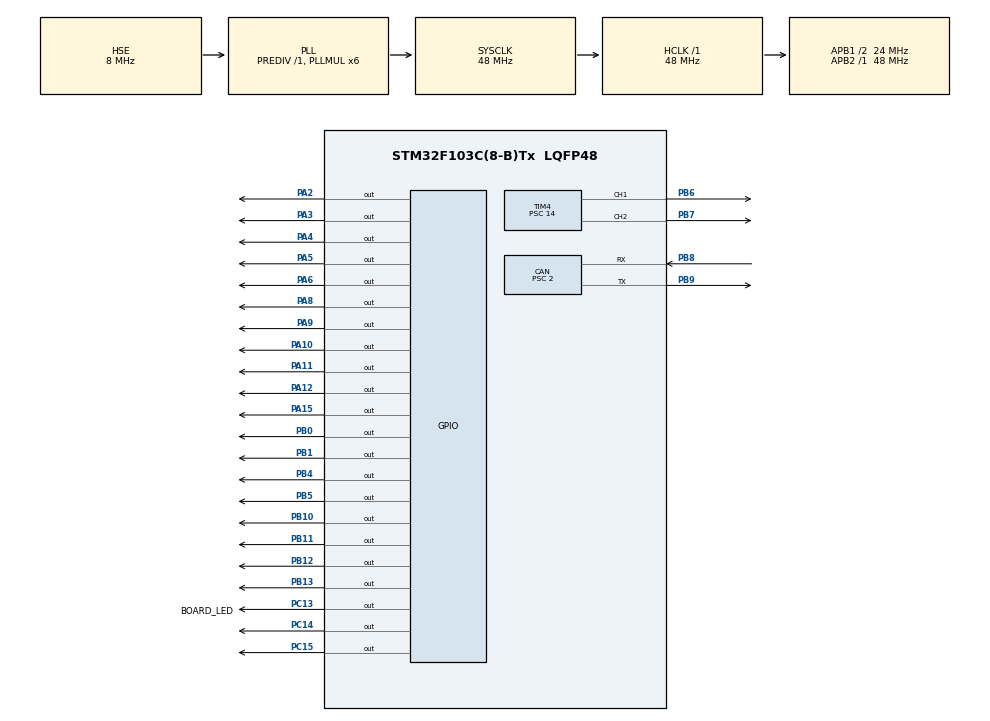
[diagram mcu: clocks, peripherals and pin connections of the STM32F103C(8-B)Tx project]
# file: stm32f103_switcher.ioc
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CAN.ABOM=ENABLE
CAN.BS1=CAN_BS1_10TQ
CAN.CalculateBaudRate=1000000
CAN.CalculateTimeBit=1000
CAN.CalculateTimeQuantum=83.33333333333333
CAN.NART=ENABLE
CAN.Prescaler=2
CAN.SJW=CAN_SJW_4TQ
FREERTOS.INCLUDE_uxTaskPriorityGet=0
FREERTOS.INCLUDE_vTaskDelayUntil=1
FREERTOS.INCLUDE_vTaskDelete=0
FREERTOS.INCLUDE_vTaskPrioritySet=0
FREERTOS.INCLUDE_vTaskSuspend=0
FREERTOS.MEMORY_ALLOCATION=1
FREERTOS.Tasks01=oamTask,-2,256,StartOamTask,As weak,NULL,Static,defaultTaskBuffer,defaultTaskControlBlock;ctrlTask,3,256,StartCtrlTask,As external,NULL,Static,ctrlTaskBuffer,ctrlTaskControlBlock;ledTask,3,128,start_led_task,As weak,NULL,Static,ledTaskBuffer,ledTaskControlBlock
FREERTOS.configENABLE_BACKWARD_COMPATIBILITY=0
FREERTOS.configGENERATE_RUN_TIME_STATS=1
FREERTOS.configIDLE_SHOULD_YIELD=0
FREERTOS.configMINIMAL_STACK_SIZE=128
FREERTOS.configRECORD_STACK_HIGH_ADDRESS=1
FREERTOS.configUSE_APPLICATION_TASK_TAG=0
FREERTOS.configUSE_MUTEXES=0
FREERTOS.configUSE_STATS_FORMATTING_FUNCTIONS=1
FREERTOS.configUSE_TRACE_FACILITY=1
FREERTOS.copyHeapFile=0
Mcu.Family=STM32F1
Mcu.Name=STM32F103C(8-B)Tx
Mcu.Package=LQFP48
NVIC.CAN1_RX1_IRQn=true\:6\:0\:true\:false\:true\:true\:true\:true\:true
NVIC.CAN1_SCE_IRQn=true\:6\:0\:true\:false\:true\:true\:true\:true\:true
NVIC.PriorityGroup=NVIC_PRIORITYGROUP_4
NVIC.TIM1_UP_IRQn=true\:15\:0\:false\:false\:true\:false\:false\:true\:true
NVIC.TimeBase=TIM1_UP_IRQn
NVIC.TimeBaseIP=TIM1
NVIC.USB_HP_CAN1_TX_IRQn=true\:6\:0\:true\:false\:true\:true\:true\:true\:true
NVIC.USB_LP_CAN1_RX0_IRQn=true\:6\:0\:true\:false\:true\:true\:true\:true\:true
PA10.Signal=GPIO_Output
PA11.Signal=GPIO_Output
PA12.Signal=GPIO_Output
PA13.Mode=Trace_Asynchronous_SW
PA13.Signal=SYS_JTMS-SWDIO
PA14.Mode=Trace_Asynchronous_SW
PA14.Signal=SYS_JTCK-SWCLK
PA15.Signal=GPIO_Output
PA2.Signal=GPIO_Output
PA3.Signal=GPIO_Output
PA4.Signal=GPIO_Output
PA5.Signal=GPIO_Output
PA6.Signal=GPIO_Output
PA8.Signal=GPIO_Output
PA9.Signal=GPIO_Output
PB0.Signal=GPIO_Output
PB1.Signal=GPIO_Output
PB10.Signal=GPIO_Output
PB11.Signal=GPIO_Output
PB12.Signal=GPIO_Output
PB13.Signal=GPIO_Output
PB3.Mode=Trace_Asynchronous_SW
PB3.Signal=SYS_JTDO-TRACESWO
PB4.Signal=GPIO_Output
PB5.Signal=GPIO_Output
PB6.Signal=S_TIM4_CH1
PB7.Signal=S_TIM4_CH2
PB8.Mode=CAN_Activate
PB8.Signal=CAN_RX
PB9.Mode=CAN_Activate
PB9.Signal=CAN_TX
PC13-TAMPER-RTC.GPIO_Label=BOARD_LED
PC13-TAMPER-RTC.Signal=GPIO_Output
PC14-OSC32_IN.Signal=GPIO_Output
PC15-OSC32_OUT.Signal=GPIO_Output
PD0-OSC_IN.Mode=HSE-External-Oscillator
PD0-OSC_IN.Signal=RCC_OSC_IN
PD1-OSC_OUT.Mode=HSE-External-Oscillator
PD1-OSC_OUT.Signal=RCC_OSC_OUT
ProjectManager.HeapSize=0x200
ProjectManager.StackSize=0x400
ProjectManager.TargetToolchain=STM32CubeIDE
RCC.AHBFreq_Value=48000000
RCC.APB1CLKDivider=RCC_HCLK_DIV2
RCC.APB1Freq_Value=24000000
RCC.APB1TimFreq_Value=48000000
RCC.APB2Freq_Value=48000000
RCC.APB2TimFreq_Value=48000000
RCC.HCLKFreq_Value=48000000
RCC.PLLMUL=RCC_PLL_MUL6
RCC.PLLSourceVirtual=RCC_PLLSOURCE_HSE
RCC.SYSCLKFreq_VALUE=48000000
RCC.SYSCLKSource=RCC_SYSCLKSOURCE_PLLCLK
RCC.USBFreq_Value=48000000
SH.S_TIM4_CH1.0=TIM4_CH1,PWM Generation1 CH1
SH.S_TIM4_CH2.0=TIM4_CH2,PWM Generation2 CH2
TIM2.Channel-PWM\ Generation1\ No\ Output=TIM_CHANNEL_1
TIM3.Channel-PWM\ Generation1\ No\ Output=TIM_CHANNEL_1
TIM4.AutoReloadPreload=TIM_AUTORELOAD_PRELOAD_ENABLE
TIM4.Channel-PWM\ Generation1\ CH1=TIM_CHANNEL_1
TIM4.Channel-PWM\ Generation2\ CH2=TIM_CHANNEL_2
TIM4.Period=64000
TIM4.Prescaler=14
TIM4.Pulse-PWM\ Generation1\ CH1=5000
TIM4.Pulse-PWM\ Generation2\ CH2=5000
VP_FREERTOS_VS_CMSIS_V1.Mode=CMSIS_V1
VP_SYS_VS_tim1.Mode=TIM1
VP_TIM2_VS_no_output1.Mode=PWM Generation1 No Output
VP_TIM3_VS_no_output1.Mode=PWM Generation1 No Output
board=custom

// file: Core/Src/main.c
/* USER CODE BEGIN Header */
/**
  ******************************************************************************
  * @file           : main.c
  * @brief          : Main program body
  ******************************************************************************
  * @attention
  *
  * Copyright (c) 2022 STMicroelectronics.
  * All rights reserved.
  *
  * This software is licensed under terms that can be found in the LICENSE file
  * in the root directory of this software component.
  * If no LICENSE file comes with this software, it is provided AS-IS.
  *
  ******************************************************************************
  */
/* USER CODE END Header */
#include "main.h"
#include "cmsis_os.h"

/* USER CODE BEGIN Includes */
#include <memory.h>

#include "trainctl_iface.h"
//#include "traincontrol.h"
//#include "canton.h"
//#include "stm32/txrxtask.h"
#include "stm32/usbtask.h"
//#include "stm32/taskauto.h"
#include "stm32/taskctrl.h"
#include "stm32/taskdisp.h"
//#include "../../../stm32dev/ina3221/ina3221.h"
#include "msg/notif.h"
//#include "config/conf_canton.h"

/* USER CODE END Includes */

CAN_HandleTypeDef hcan;

TIM_HandleTypeDef htim2;
TIM_HandleTypeDef htim3;
TIM_HandleTypeDef htim4;

osThreadId oamTaskHandle;
uint32_t defaultTaskBuffer[ 256 ];
osStaticThreadDef_t defaultTaskControlBlock;
osThreadId ctrlTaskHandle;
uint32_t ctrlTaskBuffer[ 256 ];
osStaticThreadDef_t ctrlTaskControlBlock;
osThreadId ledTaskHandle;
uint32_t ledTaskBuffer[ 128 ];
osStaticThreadDef_t ledTaskControlBlock;

void SystemClock_Config(void);
static void MX_GPIO_Init(void);
static void MX_CAN_Init(void);
static void MX_TIM4_Init(void);
static void MX_TIM2_Init(void);
static void MX_TIM3_Init(void);
void StartOamTask(void const * argument);
extern void StartCtrlTask(void const * argument);
void start_led_task(void const * argument);

int main(void)
{

  /* MCU Configuration--------------------------------------------------------*/

  /* Reset of all peripherals, Initializes the Flash interface and the Systick. */
  HAL_Init();

  /* USER CODE BEGIN Init */
//VTOR
  /* USER CODE END Init */

  /* Configure the system clock */
  SystemClock_Config();

  /* Initialize all configured peripherals */
  MX_GPIO_Init();
  MX_CAN_Init();
  MX_TIM4_Init();
  MX_TIM2_Init();
  MX_TIM3_Init();

  /* Create the thread(s) */
  /* definition and creation of oamTask */
  osThreadStaticDef(oamTask, StartOamTask, osPriorityLow, 0, 256, defaultTaskBuffer, &defaultTaskControlBlock);
  oamTaskHandle = osThreadCreate(osThread(oamTask), NULL);

  /* definition and creation of ctrlTask */
  osThreadStaticDef(ctrlTask, StartCtrlTask, osPriorityRealtime, 0, 256, ctrlTaskBuffer, &ctrlTaskControlBlock);
  ctrlTaskHandle = osThreadCreate(osThread(ctrlTask), NULL);

  /* definition and creation of ledTask */
  osThreadStaticDef(ledTask, start_led_task, osPriorityRealtime, 0, 128, ledTaskBuffer, &ledTaskControlBlock);
  ledTaskHandle = osThreadCreate(osThread(ledTask), NULL);

  /* Start scheduler */
  osKernelStart();

  /* We should never get here as control is now taken by the scheduler */
  /* Infinite loop */
  while (1)
  {

  }
}

void SystemClock_Config(void)
{
  RCC_OscInitTypeDef RCC_OscInitStruct = {0};
  RCC_ClkInitTypeDef RCC_ClkInitStruct = {0};

  /** Initializes the RCC Oscillators according to the specified parameters
  * in the RCC_OscInitTypeDef structure.
  */
  RCC_OscInitStruct.OscillatorType = RCC_OSCILLATORTYPE_HSE;
  RCC_OscInitStruct.HSEState = RCC_HSE_ON;
  RCC_OscInitStruct.HSEPredivValue = RCC_HSE_PREDIV_DIV1;
  RCC_OscInitStruct.HSIState = RCC_HSI_ON;
  RCC_OscInitStruct.PLL.PLLState = RCC_PLL_ON;
  RCC_OscInitStruct.PLL.PLLSource = RCC_PLLSOURCE_HSE;
  RCC_OscInitStruct.PLL.PLLMUL = RCC_PLL_MUL6;
  if (HAL_RCC_OscConfig(&RCC_OscInitStruct) != HAL_OK)
  {
    Error_Handler();
  }

  /** Initializes the CPU, AHB and APB buses clocks
  */
  RCC_ClkInitStruct.ClockType = RCC_CLOCKTYPE_HCLK|RCC_CLOCKTYPE_SYSCLK
                              |RCC_CLOCKTYPE_PCLK1|RCC_CLOCKTYPE_PCLK2;
  RCC_ClkInitStruct.SYSCLKSource = RCC_SYSCLKSOURCE_PLLCLK;
  RCC_ClkInitStruct.AHBCLKDivider = RCC_SYSCLK_DIV1;
  RCC_ClkInitStruct.APB1CLKDivider = RCC_HCLK_DIV2;
  RCC_ClkInitStruct.APB2CLKDivider = RCC_HCLK_DIV1;

  if (HAL_RCC_ClockConfig(&RCC_ClkInitStruct, FLASH_LATENCY_1) != HAL_OK)
  {
    Error_Handler();
  }
}

static void MX_CAN_Init(void)
{

  /* USER CODE BEGIN CAN_Init 0 */
#if 0
#define DEMCR                 *((volatile uint32_t*) 0xE000EDFCu)
#define ITM_TRACE_EN          *((volatile uint32_t*) 0xE0000E00u)

	// Enable TRCENA
	DEMCR |= ( 1 << 24);
	// Enable stimulus port 0
	ITM_TRACE_EN |= ( 1 << 0);

    //while (ITM->TCR & ITM_TCR_BUSY_Msk);
#endif
	//for (int i=0; i<1000; ) {
		itm_debug1(DBG_CAN, "MXcan", 0);
	//}
  /* USER CODE END CAN_Init 0 */

  hcan.Instance = CAN1;
  hcan.Init.Prescaler = 2;
  hcan.Init.Mode = CAN_MODE_NORMAL;
  hcan.Init.SyncJumpWidth = CAN_SJW_4TQ;
  hcan.Init.TimeSeg1 = CAN_BS1_10TQ;
  hcan.Init.TimeSeg2 = CAN_BS2_1TQ;
  hcan.Init.TimeTriggeredMode = DISABLE;
  hcan.Init.AutoBusOff = ENABLE;
  hcan.Init.AutoWakeUp = DISABLE;
  hcan.Init.AutoRetransmission = ENABLE;
  hcan.Init.ReceiveFifoLocked = DISABLE;
  hcan.Init.TransmitFifoPriority = DISABLE;
  if (HAL_CAN_Init(&hcan) != HAL_OK)
  {
    Error_Handler();
  }
  /* USER CODE BEGIN CAN_Init 2 */
	itm_debug1(DBG_CAN, "MXcan", 1);

  /* USER CODE END CAN_Init 2 */

}

static void MX_TIM2_Init(void)
{

  TIM_MasterConfigTypeDef sMasterConfig = {0};
  TIM_OC_InitTypeDef sConfigOC = {0};

  htim2.Instance = TIM2;
  htim2.Init.Prescaler = 0;
  htim2.Init.CounterMode = TIM_COUNTERMODE_UP;
  htim2.Init.Period = 65535;
  htim2.Init.ClockDivision = TIM_CLOCKDIVISION_DIV1;
  htim2.Init.AutoReloadPreload = TIM_AUTORELOAD_PRELOAD_DISABLE;
  if (HAL_TIM_PWM_Init(&htim2) != HAL_OK)
  {
    Error_Handler();
  }
  sMasterConfig.MasterOutputTrigger = TIM_TRGO_RESET;
  sMasterConfig.MasterSlaveMode = TIM_MASTERSLAVEMODE_DISABLE;
  if (HAL_TIMEx_MasterConfigSynchronization(&htim2, &sMasterConfig) != HAL_OK)
  {
    Error_Handler();
  }
  sConfigOC.OCMode = TIM_OCMODE_PWM1;
  sConfigOC.Pulse = 0;
  sConfigOC.OCPolarity = TIM_OCPOLARITY_HIGH;
  sConfigOC.OCFastMode = TIM_OCFAST_DISABLE;
  if (HAL_TIM_PWM_ConfigChannel(&htim2, &sConfigOC, TIM_CHANNEL_1) != HAL_OK)
  {
    Error_Handler();
  }

}

static void MX_TIM3_Init(void)
{

  TIM_MasterConfigTypeDef sMasterConfig = {0};
  TIM_OC_InitTypeDef sConfigOC = {0};

  htim3.Instance = TIM3;
  htim3.Init.Prescaler = 0;
  htim3.Init.CounterMode = TIM_COUNTERMODE_UP;
  htim3.Init.Period = 65535;
  htim3.Init.ClockDivision = TIM_CLOCKDIVISION_DIV1;
  htim3.Init.AutoReloadPreload = TIM_AUTORELOAD_PRELOAD_DISABLE;
  if (HAL_TIM_PWM_Init(&htim3) != HAL_OK)
  {
    Error_Handler();
  }
  sMasterConfig.MasterOutputTrigger = TIM_TRGO_RESET;
  sMasterConfig.MasterSlaveMode = TIM_MASTERSLAVEMODE_DISABLE;
  if (HAL_TIMEx_MasterConfigSynchronization(&htim3, &sMasterConfig) != HAL_OK)
  {
    Error_Handler();
  }
  sConfigOC.OCMode = TIM_OCMODE_PWM1;
  sConfigOC.Pulse = 0;
  sConfigOC.OCPolarity = TIM_OCPOLARITY_HIGH;
  sConfigOC.OCFastMode = TIM_OCFAST_DISABLE;
  if (HAL_TIM_PWM_ConfigChannel(&htim3, &sConfigOC, TIM_CHANNEL_1) != HAL_OK)
  {
    Error_Handler();
  }

}

static void MX_TIM4_Init(void)
{

  TIM_MasterConfigTypeDef sMasterConfig = {0};
  TIM_OC_InitTypeDef sConfigOC = {0};

  htim4.Instance = TIM4;
  htim4.Init.Prescaler = 14;
  htim4.Init.CounterMode = TIM_COUNTERMODE_UP;
  htim4.Init.Period = 64000;
  htim4.Init.ClockDivision = TIM_CLOCKDIVISION_DIV1;
  htim4.Init.AutoReloadPreload = TIM_AUTORELOAD_PRELOAD_ENABLE;
  if (HAL_TIM_PWM_Init(&htim4) != HAL_OK)
  {
    Error_Handler();
  }
  sMasterConfig.MasterOutputTrigger = TIM_TRGO_RESET;
  sMasterConfig.MasterSlaveMode = TIM_MASTERSLAVEMODE_DISABLE;
  if (HAL_TIMEx_MasterConfigSynchronization(&htim4, &sMasterConfig) != HAL_OK)
  {
    Error_Handler();
  }
  sConfigOC.OCMode = TIM_OCMODE_PWM1;
  sConfigOC.Pulse = 5000;
  sConfigOC.OCPolarity = TIM_OCPOLARITY_HIGH;
  sConfigOC.OCFastMode = TIM_OCFAST_DISABLE;
  if (HAL_TIM_PWM_ConfigChannel(&htim4, &sConfigOC, TIM_CHANNEL_1) != HAL_OK)
  {
    Error_Handler();
  }
  if (HAL_TIM_PWM_ConfigChannel(&htim4, &sConfigOC, TIM_CHANNEL_2) != HAL_OK)
  {
    Error_Handler();
  }
  HAL_TIM_MspPostInit(&htim4);

}

static void MX_GPIO_Init(void)
{
  GPIO_InitTypeDef GPIO_InitStruct = {0};

  /* GPIO Ports Clock Enable */
  __HAL_RCC_GPIOC_CLK_ENABLE();
  __HAL_RCC_GPIOD_CLK_ENABLE();
  __HAL_RCC_GPIOA_CLK_ENABLE();
  __HAL_RCC_GPIOB_CLK_ENABLE();

  /*Configure GPIO pin Output Level */
  HAL_GPIO_WritePin(GPIOC, BOARD_LED_Pin|GPIO_PIN_14|GPIO_PIN_15, GPIO_PIN_RESET);

  /*Configure GPIO pin Output Level */
  HAL_GPIO_WritePin(GPIOA, GPIO_PIN_2|GPIO_PIN_3|GPIO_PIN_4|GPIO_PIN_5
                          |GPIO_PIN_6|GPIO_PIN_8|GPIO_PIN_9|GPIO_PIN_10
                          |GPIO_PIN_11|GPIO_PIN_12|GPIO_PIN_15, GPIO_PIN_RESET);

  /*Configure GPIO pin Output Level */
  HAL_GPIO_WritePin(GPIOB, GPIO_PIN_0|GPIO_PIN_1|GPIO_PIN_10|GPIO_PIN_11
                          |GPIO_PIN_12|GPIO_PIN_13|GPIO_PIN_4|GPIO_PIN_5, GPIO_PIN_RESET);

  /*Configure GPIO pins : BOARD_LED_Pin PC14 PC15 */
  GPIO_InitStruct.Pin = BOARD_LED_Pin|GPIO_PIN_14|GPIO_PIN_15;
  GPIO_InitStruct.Mode = GPIO_MODE_OUTPUT_PP;
  GPIO_InitStruct.Pull = GPIO_NOPULL;
  GPIO_InitStruct.Speed = GPIO_SPEED_FREQ_LOW;
  HAL_GPIO_Init(GPIOC, &GPIO_InitStruct);

  /*Configure GPIO pins : PA2 PA3 PA4 PA5
                           PA6 PA8 PA9 PA10
                           PA11 PA12 PA15 */
  GPIO_InitStruct.Pin = GPIO_PIN_2|GPIO_PIN_3|GPIO_PIN_4|GPIO_PIN_5
                          |GPIO_PIN_6|GPIO_PIN_8|GPIO_PIN_9|GPIO_PIN_10
                          |GPIO_PIN_11|GPIO_PIN_12|GPIO_PIN_15;
  GPIO_InitStruct.Mode = GPIO_MODE_OUTPUT_PP;
  GPIO_InitStruct.Pull = GPIO_NOPULL;
  GPIO_InitStruct.Speed = GPIO_SPEED_FREQ_LOW;
  HAL_GPIO_Init(GPIOA, &GPIO_InitStruct);

  /*Configure GPIO pins : PB0 PB1 PB10 PB11
                           PB12 PB13 PB4 PB5 */
  GPIO_InitStruct.Pin = GPIO_PIN_0|GPIO_PIN_1|GPIO_PIN_10|GPIO_PIN_11
                          |GPIO_PIN_12|GPIO_PIN_13|GPIO_PIN_4|GPIO_PIN_5;
  GPIO_InitStruct.Mode = GPIO_MODE_OUTPUT_PP;
  GPIO_InitStruct.Pull = GPIO_NOPULL;
  GPIO_InitStruct.Speed = GPIO_SPEED_FREQ_LOW;
  HAL_GPIO_Init(GPIOB, &GPIO_InitStruct);

}

__weak void StartOamTask(void const * argument)
{
  for(;;)
  {
    osDelay(1);
  }
}

__weak void start_led_task(void const * argument)
{
  for(;;)
  {
    osDelay(1);
  }
}

void HAL_TIM_PeriodElapsedCallback(TIM_HandleTypeDef *htim)
{
  if (htim->Instance == TIM1) {
    HAL_IncTick();
  }
}

void Error_Handler(void)
{
  __disable_irq();
  while (1)
  {
  }
}
